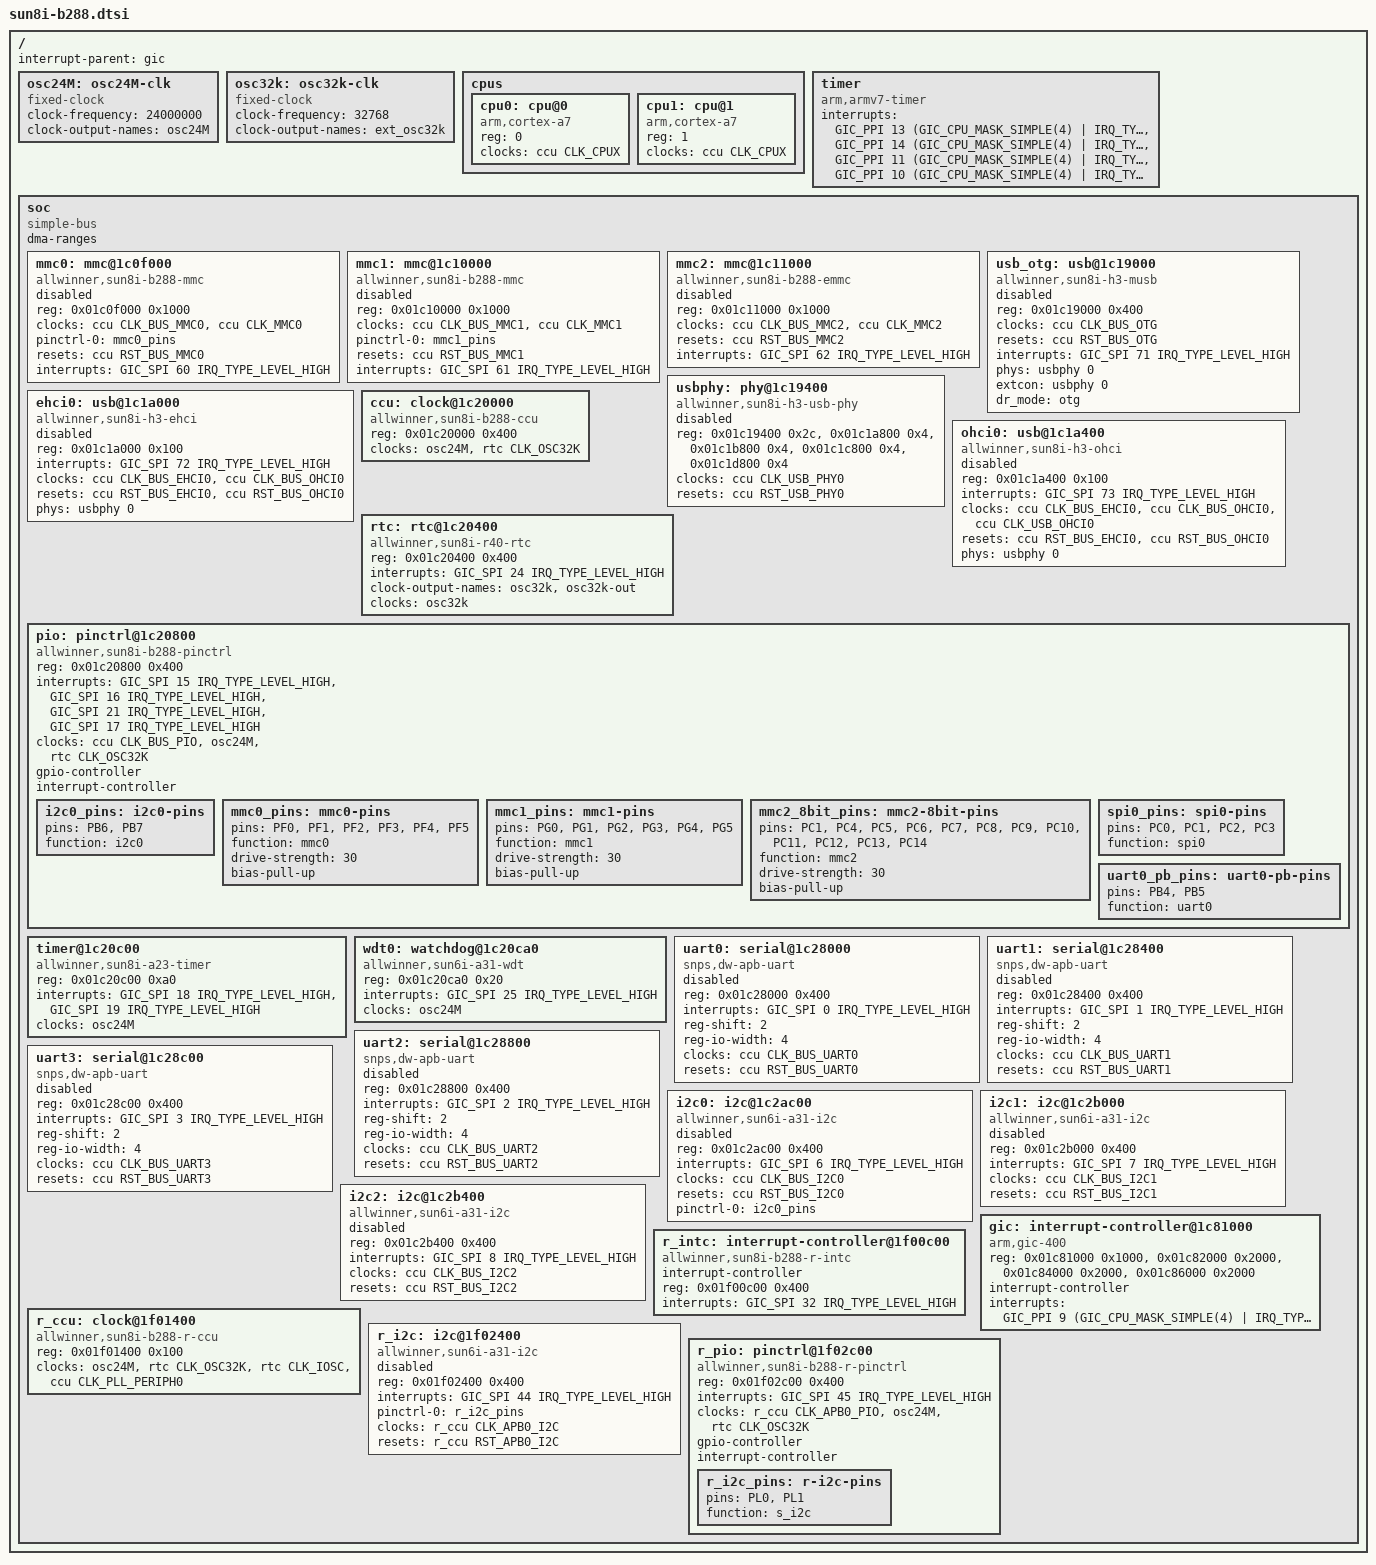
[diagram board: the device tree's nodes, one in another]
// SPDX-License-Identifier: (GPL-2.0+ OR MIT)
// Copyright (C) 2025 ARM Ltd.
// based on the Allwinner H3 dtsi:
//    Copyright (C) 2015 Jens Kuske <jenskuske@gmail.com>

#include <dt-bindings/clock/sun8i-b288-ccu.h>
#include <dt-bindings/clock/sun6i-rtc.h>
#include <dt-bindings/clock/sun8i-r-ccu.h>
#include <dt-bindings/interrupt-controller/arm-gic.h>
#include <dt-bindings/reset/sun8i-b288-ccu.h>
#include <dt-bindings/reset/sun8i-r-ccu.h>

/ {
	interrupt-parent = <&gic>;
	#address-cells = <1>;
	#size-cells = <1>;

	osc24M: osc24M-clk {
		#clock-cells = <0>;
		compatible = "fixed-clock";
		clock-frequency = <24000000>;
		clock-output-names = "osc24M";
	};

	osc32k: osc32k-clk {
		#clock-cells = <0>;
		compatible = "fixed-clock";
		clock-frequency = <32768>;
		clock-output-names = "ext_osc32k";
	};

	cpus {
		#address-cells = <1>;
		#size-cells = <0>;

		cpu0: cpu@0 {
			compatible = "arm,cortex-a7";
			device_type = "cpu";
			reg = <0>;
			clocks = <&ccu CLK_CPUX>;
			clock-names = "cpu";
		};

		cpu1: cpu@1 {
			compatible = "arm,cortex-a7";
			device_type = "cpu";
			reg = <1>;
			clocks = <&ccu CLK_CPUX>;
			clock-names = "cpu";
		};
	};

	timer {
		compatible = "arm,armv7-timer";
		interrupts = <GIC_PPI 13 (GIC_CPU_MASK_SIMPLE(4) | IRQ_TYPE_LEVEL_LOW )>,
			<GIC_PPI 14 (GIC_CPU_MASK_SIMPLE(4) | IRQ_TYPE_LEVEL_LOW )>,
			<GIC_PPI 11 (GIC_CPU_MASK_SIMPLE(4) | IRQ_TYPE_LEVEL_LOW )>,
			<GIC_PPI 10 (GIC_CPU_MASK_SIMPLE(4) | IRQ_TYPE_LEVEL_LOW )>;
	};

	soc {
		compatible = "simple-bus";
		#address-cells = <1>;
		#size-cells = <1>;
		dma-ranges;
		ranges;

		mmc0: mmc@1c0f000 {
			compatible = "allwinner,sun8i-b288-mmc",
				     "allwinner,sun50i-a64-mmc";
			reg = <0x01c0f000 0x1000>;
			clocks = <&ccu CLK_BUS_MMC0>, <&ccu CLK_MMC0>;
			clock-names = "ahb", "mmc";
			pinctrl-names = "default";
			pinctrl-0 = <&mmc0_pins>;
			resets = <&ccu RST_BUS_MMC0>;
			reset-names = "ahb";
			interrupts = <GIC_SPI 60 IRQ_TYPE_LEVEL_HIGH>;
			status = "disabled";
			#address-cells = <1>;
			#size-cells = <0>;
		};

		mmc1: mmc@1c10000 {
			compatible = "allwinner,sun8i-b288-mmc",
				     "allwinner,sun50i-a64-mmc";
			reg = <0x01c10000 0x1000>;
			clocks = <&ccu CLK_BUS_MMC1>, <&ccu CLK_MMC1>;
			clock-names = "ahb", "mmc";
			pinctrl-names = "default";
			pinctrl-0 = <&mmc1_pins>;
			resets = <&ccu RST_BUS_MMC1>;
			reset-names = "ahb";
			interrupts = <GIC_SPI 61 IRQ_TYPE_LEVEL_HIGH>;
			status = "disabled";
			#address-cells = <1>;
			#size-cells = <0>;
		};

		mmc2: mmc@1c11000 {
			compatible = "allwinner,sun8i-b288-emmc",
				     "allwinner,sun50i-a64-emmc";
			reg = <0x01c11000 0x1000>;
			clocks = <&ccu CLK_BUS_MMC2>, <&ccu CLK_MMC2>;
			clock-names = "ahb", "mmc";
			resets = <&ccu RST_BUS_MMC2>;
			reset-names = "ahb";
			interrupts = <GIC_SPI 62 IRQ_TYPE_LEVEL_HIGH>;
			status = "disabled";
			#address-cells = <1>;
			#size-cells = <0>;
		};

		usb_otg: usb@1c19000 {
			compatible = "allwinner,sun8i-h3-musb";
			reg = <0x01c19000 0x400>;
			clocks = <&ccu CLK_BUS_OTG>;
			resets = <&ccu RST_BUS_OTG>;
			interrupts = <GIC_SPI 71 IRQ_TYPE_LEVEL_HIGH>;
			interrupt-names = "mc";
			phys = <&usbphy 0>;
			phy-names = "usb";
			extcon = <&usbphy 0>;
			dr_mode = "otg";
			status = "disabled";
		};

		usbphy: phy@1c19400 {
			compatible = "allwinner,sun8i-h3-usb-phy";
			reg = <0x01c19400 0x2c>,
			      <0x01c1a800 0x4>,
			      <0x01c1b800 0x4>,
			      <0x01c1c800 0x4>,
			      <0x01c1d800 0x4>;
			reg-names = "phy_ctrl",
				    "pmu0",
				    "pmu1",
				    "pmu2",
				    "pmu3";
			clocks = <&ccu CLK_USB_PHY0>;
			clock-names = "usb0_phy";
			resets = <&ccu RST_USB_PHY0>;
			reset-names = "usb0_reset";
			status = "disabled";
			#phy-cells = <1>;
		};

		ehci0: usb@1c1a000 {
			compatible = "allwinner,sun8i-h3-ehci", "generic-ehci";
			reg = <0x01c1a000 0x100>;
			interrupts = <GIC_SPI 72 IRQ_TYPE_LEVEL_HIGH>;
			clocks = <&ccu CLK_BUS_EHCI0>, <&ccu CLK_BUS_OHCI0>;
			resets = <&ccu RST_BUS_EHCI0>, <&ccu RST_BUS_OHCI0>;
			phys = <&usbphy 0>;
			phy-names = "usb";
			status = "disabled";
		};

		ohci0: usb@1c1a400 {
			compatible = "allwinner,sun8i-h3-ohci", "generic-ohci";
			reg = <0x01c1a400 0x100>;
			interrupts = <GIC_SPI 73 IRQ_TYPE_LEVEL_HIGH>;
			clocks = <&ccu CLK_BUS_EHCI0>, <&ccu CLK_BUS_OHCI0>,
				 <&ccu CLK_USB_OHCI0>;
			resets = <&ccu RST_BUS_EHCI0>, <&ccu RST_BUS_OHCI0>;
			phys = <&usbphy 0>;
			phy-names = "usb";
			status = "disabled";
		};

		ccu: clock@1c20000 {
			compatible = "allwinner,sun8i-b288-ccu";
			reg = <0x01c20000 0x400>;
			clocks = <&osc24M>, <&rtc CLK_OSC32K>;
			clock-names = "hosc", "losc";
			#clock-cells = <1>;
			#reset-cells = <1>;
		};

		rtc: rtc@1c20400 {
			compatible = "allwinner,sun8i-r40-rtc";
			reg = <0x01c20400 0x400>;
			interrupts = <GIC_SPI 24 IRQ_TYPE_LEVEL_HIGH>;
			clock-output-names = "osc32k", "osc32k-out";
			clocks = <&osc32k>;
			#clock-cells = <1>;
		};

		pio: pinctrl@1c20800 {
			compatible = "allwinner,sun8i-b288-pinctrl";
			reg = <0x01c20800 0x400>;
			interrupts = <GIC_SPI 15 IRQ_TYPE_LEVEL_HIGH>,
				     <GIC_SPI 16 IRQ_TYPE_LEVEL_HIGH>,
				     <GIC_SPI 21 IRQ_TYPE_LEVEL_HIGH>,
				     <GIC_SPI 17 IRQ_TYPE_LEVEL_HIGH>;
			clocks = <&ccu CLK_BUS_PIO>, <&osc24M>,
				 <&rtc CLK_OSC32K>;
			clock-names = "apb", "hosc", "losc";
			gpio-controller;
			#gpio-cells = <3>;
			interrupt-controller;
			#interrupt-cells = <3>;

			i2c0_pins: i2c0-pins {
				pins = "PB6", "PB7";
				function = "i2c0";
			};

			mmc0_pins: mmc0-pins {
				pins = "PF0", "PF1", "PF2", "PF3",
				       "PF4", "PF5";
				function = "mmc0";
				drive-strength = <30>;
				bias-pull-up;
			};

			mmc1_pins: mmc1-pins {
				pins = "PG0", "PG1", "PG2", "PG3",
				       "PG4", "PG5";
				function = "mmc1";
				drive-strength = <30>;
				bias-pull-up;
			};

			mmc2_8bit_pins: mmc2-8bit-pins {
				pins = "PC1", "PC4", "PC5", "PC6",
				       "PC7", "PC8", "PC9", "PC10",
				       "PC11", "PC12", "PC13", "PC14";
				function = "mmc2";
				drive-strength = <30>;
				bias-pull-up;
			};

			spi0_pins: spi0-pins {
				pins = "PC0", "PC1", "PC2", "PC3";
				function = "spi0";
			};

			uart0_pb_pins: uart0-pb-pins {
				pins = "PB4", "PB5";
				function = "uart0";
			};
		};

		timer@1c20c00 {
			compatible = "allwinner,sun8i-a23-timer";
			reg = <0x01c20c00 0xa0>;
			interrupts = <GIC_SPI 18 IRQ_TYPE_LEVEL_HIGH>,
				     <GIC_SPI 19 IRQ_TYPE_LEVEL_HIGH>;
			clocks = <&osc24M>;
		};

		wdt0: watchdog@1c20ca0 {
			compatible = "allwinner,sun6i-a31-wdt";
			reg = <0x01c20ca0 0x20>;
			interrupts = <GIC_SPI 25 IRQ_TYPE_LEVEL_HIGH>;
			clocks = <&osc24M>;
		};

		uart0: serial@1c28000 {
			compatible = "snps,dw-apb-uart";
			reg = <0x01c28000 0x400>;
			interrupts = <GIC_SPI 0 IRQ_TYPE_LEVEL_HIGH>;
			reg-shift = <2>;
			reg-io-width = <4>;
			clocks = <&ccu CLK_BUS_UART0>;
			resets = <&ccu RST_BUS_UART0>;
			status = "disabled";
		};

		uart1: serial@1c28400 {
			compatible = "snps,dw-apb-uart";
			reg = <0x01c28400 0x400>;
			interrupts = <GIC_SPI 1 IRQ_TYPE_LEVEL_HIGH>;
			reg-shift = <2>;
			reg-io-width = <4>;
			clocks = <&ccu CLK_BUS_UART1>;
			resets = <&ccu RST_BUS_UART1>;
			status = "disabled";
		};

		uart2: serial@1c28800 {
			compatible = "snps,dw-apb-uart";
			reg = <0x01c28800 0x400>;
			interrupts = <GIC_SPI 2 IRQ_TYPE_LEVEL_HIGH>;
			reg-shift = <2>;
			reg-io-width = <4>;
			clocks = <&ccu CLK_BUS_UART2>;
			resets = <&ccu RST_BUS_UART2>;
			status = "disabled";
		};

		uart3: serial@1c28c00 {
			compatible = "snps,dw-apb-uart";
			reg = <0x01c28c00 0x400>;
			interrupts = <GIC_SPI 3 IRQ_TYPE_LEVEL_HIGH>;
			reg-shift = <2>;
			reg-io-width = <4>;
			clocks = <&ccu CLK_BUS_UART3>;
			resets = <&ccu RST_BUS_UART3>;
			status = "disabled";
		};

		i2c0: i2c@1c2ac00 {
			compatible = "allwinner,sun6i-a31-i2c";
			reg = <0x01c2ac00 0x400>;
			interrupts = <GIC_SPI 6 IRQ_TYPE_LEVEL_HIGH>;
			clocks = <&ccu CLK_BUS_I2C0>;
			resets = <&ccu RST_BUS_I2C0>;
			pinctrl-names = "default";
			pinctrl-0 = <&i2c0_pins>;
			status = "disabled";
			#address-cells = <1>;
			#size-cells = <0>;
		};

		i2c1: i2c@1c2b000 {
			compatible = "allwinner,sun6i-a31-i2c";
			reg = <0x01c2b000 0x400>;
			interrupts = <GIC_SPI 7 IRQ_TYPE_LEVEL_HIGH>;
			clocks = <&ccu CLK_BUS_I2C1>;
			resets = <&ccu RST_BUS_I2C1>;
			status = "disabled";
			#address-cells = <1>;
			#size-cells = <0>;
		};

		i2c2: i2c@1c2b400 {
			compatible = "allwinner,sun6i-a31-i2c";
			reg = <0x01c2b400 0x400>;
			interrupts = <GIC_SPI 8 IRQ_TYPE_LEVEL_HIGH>;
			clocks = <&ccu CLK_BUS_I2C2>;
			resets = <&ccu RST_BUS_I2C2>;
			status = "disabled";
			#address-cells = <1>;
			#size-cells = <0>;
		};

		gic: interrupt-controller@1c81000 {
			compatible = "arm,gic-400";
			reg = <0x01c81000 0x1000>,
			      <0x01c82000 0x2000>,
			      <0x01c84000 0x2000>,
			      <0x01c86000 0x2000>;
			interrupt-controller;
			#interrupt-cells = <3>;
			interrupts = <GIC_PPI 9 (GIC_CPU_MASK_SIMPLE(4) | IRQ_TYPE_LEVEL_HIGH)>;
		};

		r_intc: interrupt-controller@1f00c00 {
			compatible = "allwinner,sun8i-b288-r-intc",
				     "allwinner,sun6i-a31-r-intc";
			interrupt-controller;
			#interrupt-cells = <3>;
			reg = <0x01f00c00 0x400>;
			interrupts = <GIC_SPI 32 IRQ_TYPE_LEVEL_HIGH>;
		};

		r_ccu: clock@1f01400 {
			compatible = "allwinner,sun8i-b288-r-ccu";
			reg = <0x01f01400 0x100>;
			clocks = <&osc24M>, <&rtc CLK_OSC32K>, <&rtc CLK_IOSC>,
				 <&ccu CLK_PLL_PERIPH0>;
			clock-names = "hosc", "losc", "iosc", "pll-periph";
			#clock-cells = <1>;
			#reset-cells = <1>;
		};

		r_i2c: i2c@1f02400 {
			compatible = "allwinner,sun6i-a31-i2c";
			reg = <0x01f02400 0x400>;
			interrupts = <GIC_SPI 44 IRQ_TYPE_LEVEL_HIGH>;
			pinctrl-names = "default";
			pinctrl-0 = <&r_i2c_pins>;
			clocks = <&r_ccu CLK_APB0_I2C>;
			resets = <&r_ccu RST_APB0_I2C>;
			status = "disabled";
			#address-cells = <1>;
			#size-cells = <0>;
		};

		r_pio: pinctrl@1f02c00 {
			compatible = "allwinner,sun8i-b288-r-pinctrl",
				     "allwinner,sun8i-h3-r-pinctrl";
			reg = <0x01f02c00 0x400>;
			interrupts = <GIC_SPI 45 IRQ_TYPE_LEVEL_HIGH>;
			clocks = <&r_ccu CLK_APB0_PIO>, <&osc24M>,
				 <&rtc CLK_OSC32K>;
			clock-names = "apb", "hosc", "losc";
			gpio-controller;
			#gpio-cells = <3>;
			interrupt-controller;
			#interrupt-cells = <3>;

			r_i2c_pins: r-i2c-pins {
				pins = "PL0", "PL1";
				function = "s_i2c";
			};
		};
	};
};
